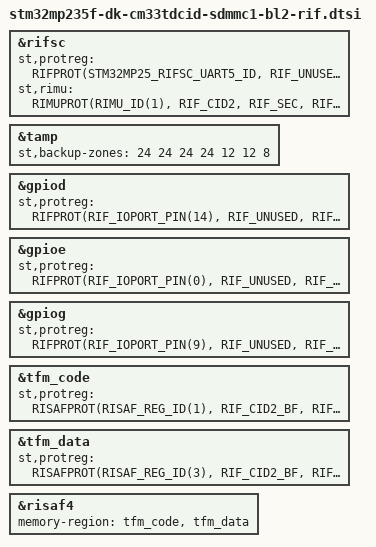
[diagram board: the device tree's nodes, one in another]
/*
 * Copyright (c) 2026, STMicroelectronics - All Rights Reserved
 *
 * SPDX-License-Identifier: Apache-2.0
 */

&rifsc {
	st,protreg = <
		RIFPROT(STM32MP25_RIFSC_UART5_ID, RIF_UNUSED, RIF_UNLOCK, RIF_SEC, RIF_PRIV, RIF_CID2, RIF_SEM_DIS, RIF_CFEN)
		RIFPROT(STM32MP25_RIFSC_I2C7_ID, RIF_UNUSED, RIF_UNLOCK, RIF_SEC, RIF_PRIV, RIF_CID2, RIF_SEM_DIS, RIF_CFEN)
		RIFPROT(STM32MP25_RIFSC_SDMMC1_ID, RIF_UNUSED, RIF_UNLOCK, RIF_SEC, RIF_PRIV, RIF_CID2, RIF_SEM_DIS, RIF_CFEN)
		RIFPROT(STM32MP25_RIFSC_RNG_ID, RIF_UNUSED, RIF_UNLOCK, RIF_SEC, RIF_PRIV, RIF_CID2, RIF_SEM_DIS, RIF_CFEN)
	>;
};

&tamp {
	st,backup-zones = <24 24 24 24 12 12 8>;
};

&gpiod {
	st,protreg = <
		RIFPROT(RIF_IOPORT_PIN(14), RIF_UNUSED, RIF_UNLOCK, RIF_SEC, RIF_PRIV, RIF_CID2, RIF_SEM_DIS, RIF_CFEN)
		RIFPROT(RIF_IOPORT_PIN(15), RIF_UNUSED, RIF_UNLOCK, RIF_SEC, RIF_PRIV, RIF_CID2, RIF_SEM_DIS, RIF_CFEN)
	>;
};

&gpioe {
	st,protreg = <
		RIFPROT(RIF_IOPORT_PIN(0), RIF_UNUSED, RIF_UNLOCK, RIF_SEC, RIF_PRIV, RIF_CID2, RIF_SEM_DIS, RIF_CFEN)
		RIFPROT(RIF_IOPORT_PIN(1), RIF_UNUSED, RIF_UNLOCK, RIF_SEC, RIF_PRIV, RIF_CID2, RIF_SEM_DIS, RIF_CFEN)
		RIFPROT(RIF_IOPORT_PIN(2), RIF_UNUSED, RIF_UNLOCK, RIF_SEC, RIF_PRIV, RIF_CID2, RIF_SEM_DIS, RIF_CFEN)
		RIFPROT(RIF_IOPORT_PIN(3), RIF_UNUSED, RIF_UNLOCK, RIF_SEC, RIF_PRIV, RIF_CID2, RIF_SEM_DIS, RIF_CFEN)
		RIFPROT(RIF_IOPORT_PIN(4), RIF_UNUSED, RIF_UNLOCK, RIF_SEC, RIF_PRIV, RIF_CID2, RIF_SEM_DIS, RIF_CFEN)
		RIFPROT(RIF_IOPORT_PIN(5), RIF_UNUSED, RIF_UNLOCK, RIF_SEC, RIF_PRIV, RIF_CID2, RIF_SEM_DIS, RIF_CFEN)
	>;
};

&gpiog {
	st,protreg = <
		RIFPROT(RIF_IOPORT_PIN(9), RIF_UNUSED, RIF_UNLOCK, RIF_SEC, RIF_PRIV, RIF_CID2, RIF_SEM_DIS, RIF_CFEN)
		RIFPROT(RIF_IOPORT_PIN(10), RIF_UNUSED, RIF_UNLOCK, RIF_SEC, RIF_PRIV, RIF_CID2, RIF_SEM_DIS, RIF_CFEN)
	>;
};

&rifsc {
	st,rimu = <
		RIMUPROT(RIMU_ID(1), RIF_CID2, RIF_SEC, RIF_PRIV, RIF_CIDSEL_M)
	>;
};

&tfm_code {
	st,protreg = <RISAFPROT(RISAF_REG_ID(1), RIF_CID2_BF, RIF_CID2_BF, RIF_UNUSED, RIF_SEC, RIF_ENC_EN, RIF_BREN_EN)>;
};

&tfm_data {
	st,protreg = <RISAFPROT(RISAF_REG_ID(3), RIF_CID2_BF, RIF_CID2_BF, RIF_UNUSED, RIF_SEC, RIF_ENC_EN, RIF_BREN_EN)>;
};

&risaf4 {
	memory-region = <&tfm_code>, <&tfm_data>;
};
